VERSION "1.0"

NS_ :

BS_:

BU_: DUT Tester

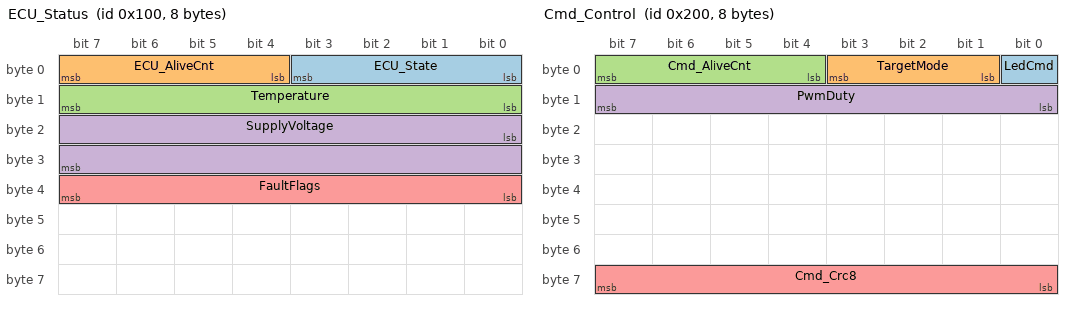
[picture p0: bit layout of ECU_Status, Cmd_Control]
BO_ 256 ECU_Status: 8 DUT
 SG_ ECU_State : 0|4@1+ (1,0) [0|15] "" Tester
 SG_ ECU_AliveCnt : 4|4@1+ (1,0) [0|15] "" Tester
 SG_ Temperature : 8|8@1+ (1,-40) [-40|215] "degC" Tester
 SG_ SupplyVoltage : 16|16@1+ (0.01,0) [0|655.35] "V" Tester
 SG_ FaultFlags : 32|8@1+ (1,0) [0|255] "" Tester

BO_ 512 Cmd_Control: 8 Tester
 SG_ LedCmd : 0|1@1+ (1,0) [0|1] "" DUT
 SG_ TargetMode : 1|3@1+ (1,0) [0|7] "" DUT
 SG_ Cmd_AliveCnt : 4|4@1+ (1,0) [0|15] "" DUT
 SG_ PwmDuty : 8|8@1+ (0.5,0) [0|100] "%" DUT
 SG_ Cmd_Crc8 : 56|8@1+ (1,0) [0|255] "" DUT

BO_ 768 Fault_Event: 2 DUT
 SG_ FaultCode : 0|8@1+ (1,0) [0|255] "" Tester
 SG_ FaultActive : 8|1@1+ (1,0) [0|1] "" Tester

CM_ BU_ DUT "Device under test: the ECU whose minimal system is being initialized";
CM_ BU_ Tester "Test / simulation node (rest-bus simulation or CAN tool)";
CM_ BO_ 256 "Cyclic status message of DUT, 100 ms";
CM_ SG_ 256 ECU_State "ECU state machine";
CM_ SG_ 256 ECU_AliveCnt "Alive counter, +1 per transmission, wraps 15 -> 0";
CM_ SG_ 256 Temperature "Board temperature, physical = raw - 40";
CM_ SG_ 256 SupplyVoltage "Supply voltage, resolution 10 mV";
CM_ SG_ 256 FaultFlags "bit0: CmdTimeout, bit1: CmdCrcError, bit2: CmdAliveError, bit3: UnderVoltage";
CM_ BO_ 512 "Cyclic control command from Tester, 100 ms; DUT timeout 500 ms";
CM_ SG_ 512 Cmd_Crc8 "CRC8 SAE J1850 (poly 0x1D, init 0xFF, xorout 0xFF) over bytes 0..6";
CM_ SG_ 512 PwmDuty "PWM duty command, physical = raw * 0.5, 0..100 %";
CM_ BO_ 768 "Event-triggered fault message, sent once on fault state change";

BA_DEF_ "BusType" STRING ;
BA_DEF_ "Baudrate" INT 0 1000000;
BA_DEF_ BO_ "GenMsgCycleTime" INT 0 65535;
BA_DEF_ BO_ "GenMsgSendType" ENUM "Cyclic","Event";
BA_DEF_DEF_ "BusType" "CAN";
BA_DEF_DEF_ "Baudrate" 500000;
BA_DEF_DEF_ "GenMsgCycleTime" 0;
BA_DEF_DEF_ "GenMsgSendType" "Cyclic";
BA_ "GenMsgCycleTime" BO_ 256 100;
BA_ "GenMsgCycleTime" BO_ 512 100;
BA_ "GenMsgSendType" BO_ 768 1;

VAL_ 256 ECU_State 0 "Init" 1 "Standby" 2 "Normal" 3 "Fault";
VAL_ 512 TargetMode 0 "Off" 1 "Standby" 2 "Normal";
VAL_ 512 LedCmd 0 "Off" 1 "On";
VAL_ 768 FaultCode 0 "NoFault" 1 "CmdTimeout" 2 "CmdCrcError" 3 "CmdAliveError" 4 "UnderVoltage";
VAL_ 768 FaultActive 0 "Cleared" 1 "Active";
